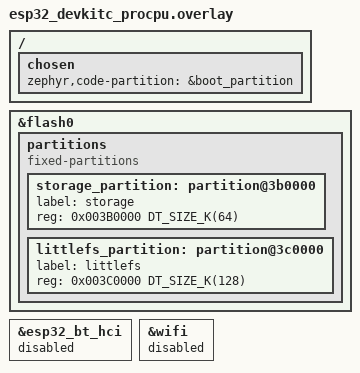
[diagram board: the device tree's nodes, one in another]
/**
 * @file      esp32_devkitc_procpu.overlay
 * @brief     esp32-devkitc board mcuboot overlay
 *
 * Copyright joelguittet and mender-mcu-client contributors
 *
 * Licensed under the Apache License, Version 2.0 (the "License");
 * you may not use this file except in compliance with the License.
 * You may obtain a copy of the License at
 *
 *     http://www.apache.org/licenses/LICENSE-2.0
 *
 * Unless required by applicable law or agreed to in writing, software
 * distributed under the License is distributed on an "AS IS" BASIS,
 * WITHOUT WARRANTIES OR CONDITIONS OF ANY KIND, either express or implied.
 * See the License for the specific language governing permissions and
 * limitations under the License.
 */

/delete-node/ &storage_partition;

/ {
    chosen {
        zephyr,code-partition = &boot_partition;
    };
};

&flash0 {
    status = "okay";
    partitions {
        compatible = "fixed-partitions";
        #address-cells = <1>;
        #size-cells = <1>;
        ranges;
        /* Storage slot: 64KB */
        storage_partition: partition@3b0000 {
            label = "storage";
            reg = <0x003B0000 DT_SIZE_K(64)>;
        };
        /* LittleFS slot: 128KB */
        littlefs_partition: partition@3c0000 {
            label = "littlefs";
            reg = <0x003C0000 DT_SIZE_K(128)>;
        };
    };
};

&esp32_bt_hci {
    status = "disabled";
};

&wifi {
    status = "disabled";
};
